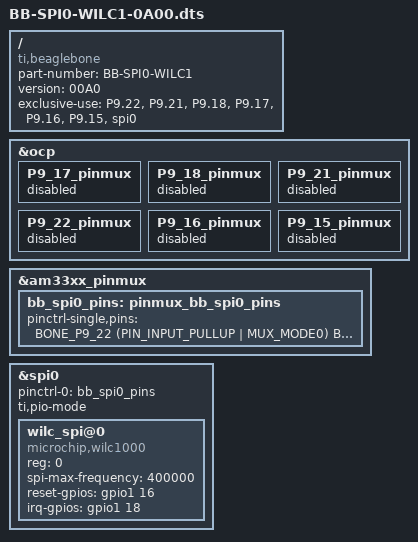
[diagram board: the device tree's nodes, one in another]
/*
 * Copyright (C) 2015 Robert Nelson <robertcnelson@gmail.com>
 *
 * This program is free software; you can redistribute it and/or modify
 * it under the terms of the GNU General Public License version 2 as
 * published by the Free Software Foundation.
 */

/dts-v1/;
/plugin/;

#include <dt-bindings/board/am335x-bbw-bbb-base.h>
#include <dt-bindings/pinctrl/am33xx.h>

/ {
	compatible = "ti,beaglebone", "ti,beaglebone-black", "ti,beaglebone-green";

	/* identification */
	part-number = "BB-SPI0-WILC1";
	version = "00A0";

	/* state the resources this cape uses */
	exclusive-use =
		/* the pin header uses */
		"P9.22",	/* spi0_sclk, SPI0_SCLK */
		"P9.21",	/* spi0_d0, SPI0_MISO */
		"P9.18",	/* spi0_d1, SPI0_MOSI */
		"P9.17",	/* spi0_cs0, CS0 */
		"P9.16",	/* IRQ io pin */
		"P9.15",	/* Reset io pin */
		/* the hardware ip uses */
		"spi0";

	/*
	 * Free up the pins used by the cape from the pinmux helpers.
	 */
	fragment@0 {
		target = <&ocp>;
		__overlay__ {
			P9_17_pinmux { status = "disabled"; };	/* spi0_cs0 */
			P9_18_pinmux { status = "disabled"; };	/* spi0_d1 */
			P9_21_pinmux { status = "disabled"; };	/* spi0_d0 */
			P9_22_pinmux { status = "disabled"; };	/* spi0_sclk */
			P9_16_pinmux { status = "disabled"; };	/* IRQ */
			P9_15_pinmux { status = "disabled"; };	/* RESET */
		};
	};

	fragment@1 {
		target = <&am33xx_pinmux>;
		__overlay__ {
			bb_spi0_pins: pinmux_bb_spi0_pins {
				pinctrl-single,pins = <
					BONE_P9_22 (PIN_INPUT_PULLUP | MUX_MODE0) /* spi0_sclk.spi0_sclk */
					BONE_P9_21 (PIN_INPUT_PULLUP | MUX_MODE0) /* spi0_d0.spi0_d0 */
					BONE_P9_18 (PIN_OUTPUT_PULLUP | MUX_MODE0) /* spi0_d0.spi0_d1 */
					BONE_P9_17 (PIN_OUTPUT_PULLUP | MUX_MODE0)  /* spi0_cs0.spi0_cs0 */
					BONE_P9_16 (PIN_INPUT_PULLUP | MUX_MODE7)  /* irq for wifi chip */
					BONE_P9_15 (PIN_OUTPUT_PULLUP | MUX_MODE7)  /* reset for spi chip */
				>;
			};
		};
	};

	fragment@2 {
		target = <&spi0>;
		__overlay__ {
			#address-cells = <1>;
			#size-cells = <0>;

			status = "okay";
			pinctrl-names = "default";
			pinctrl-0 = <&bb_spi0_pins>;
			ti,pio-mode; /* disable dma when used as an overlay, dma gets stuck at 160 bits... */

            wilc_spi@0 {
                compatible = "microchip,wilc1000", "microchip,wilc3000";
                reg = <0>;
                spi-max-frequency = <400000>;
                reset-gpios = <&gpio1 16 0>;
                irq-gpios = <&gpio1 18 0>;
                status = "okay";
            };
		};
	};
};

